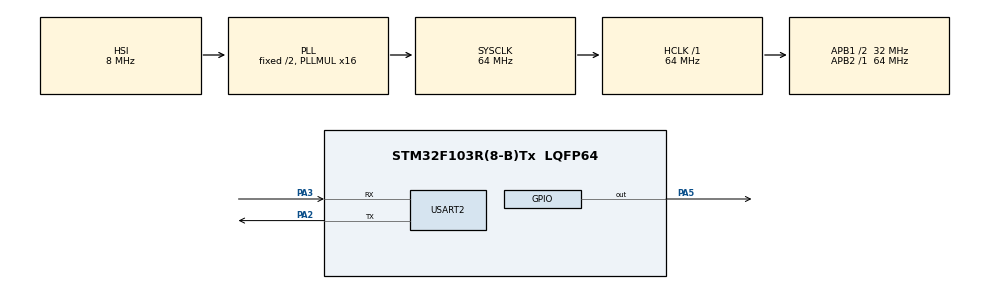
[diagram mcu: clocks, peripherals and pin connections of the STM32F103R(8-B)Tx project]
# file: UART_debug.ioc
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Mcu.Family=STM32F1
RCC.APB1CLKDivider=RCC_HCLK_DIV2
RCC.SYSCLKSource=RCC_SYSCLKSOURCE_PLLCLK
ProjectManager.StackSize=0x400
PA13.Signal=SYS_JTMS-SWDIO
PA3.Mode=Asynchronous
ProjectManager.TargetToolchain=STM32CubeIDE
RCC.HCLKFreq_Value=64000000
RCC.APB2TimFreq_Value=64000000
RCC.USBFreq_Value=64000000
RCC.AHBFreq_Value=64000000
PA5.Signal=GPIO_Output
board=custom
RCC.PLLMUL=RCC_PLL_MUL16
RCC.APB2Freq_Value=64000000
PA14.Mode=Serial_Wire
PA13.Mode=Serial_Wire
Mcu.Name=STM32F103R(8-B)Tx
PA2.Signal=USART2_TX
RCC.SYSCLKFreq_VALUE=64000000
Mcu.Package=LQFP64
USART2.VirtualMode=VM_ASYNC
PA14.Signal=SYS_JTCK-SWCLK
ProjectManager.HeapSize=0x200
NVIC.PriorityGroup=NVIC_PRIORITYGROUP_4
RCC.APB1TimFreq_Value=64000000
PA2.Mode=Asynchronous
RCC.APB1Freq_Value=32000000
PA3.Signal=USART2_RX

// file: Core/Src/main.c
/* USER CODE BEGIN Header */
/**
  ******************************************************************************
  * @file           : main.c
  * @brief          : Main program body
  ******************************************************************************
  * @attention
  *
  * <h2><center>&copy; Copyright (c) 2021 STMicroelectronics.
  * All rights reserved.</center></h2>
  *
  * This software component is licensed by ST under Ultimate Liberty license
  * SLA0044, the "License"; You may not use this file except in compliance with
  * the License. You may obtain a copy of the License at:
  *                             www.st.com/SLA0044
  *
  ******************************************************************************
  */
/* USER CODE END Header */
#include "main.h"

UART_HandleTypeDef huart2;

void SystemClock_Config(void);
static void MX_GPIO_Init(void);
static void MX_USART2_UART_Init(void);
/* USER CODE BEGIN PFP */
// uint8_t CDC_Transmit_FS(uint8_t* Buf, uint16_t Len);
/* USER CODE END PFP */

int main(void)
{

  /* MCU Configuration--------------------------------------------------------*/

  /* Reset of all peripherals, Initializes the Flash interface and the Systick. */
  HAL_Init();

  /* Configure the system clock */
  SystemClock_Config();

  /* Initialize all configured peripherals */
  MX_GPIO_Init();
  MX_USART2_UART_Init();
  /* USER CODE BEGIN 2 */
  uint8_t data[256];
  HAL_StatusTypeDef s;
  uint8_t *string;
  /* USER CODE END 2 */

  /* Infinite loop */
  /* USER CODE BEGIN WHILE */
  while (1)
  {
	string = "Timeout /r/n";
	s = HAL_UART_Receive(&huart2, data, 1, 3000);
	if(s == HAL_TIMEOUT){
		HAL_UART_Transmit(&huart2, string, 15, 10);
	}else if(s == HAL_OK){
		HAL_UART_Transmit(&huart2, data, 1, 10);
	}
    /* USER CODE END WHILE */

  }
}

void SystemClock_Config(void)
{
  RCC_OscInitTypeDef RCC_OscInitStruct = {0};
  RCC_ClkInitTypeDef RCC_ClkInitStruct = {0};

  /** Initializes the RCC Oscillators according to the specified parameters
  * in the RCC_OscInitTypeDef structure.
  */
  RCC_OscInitStruct.OscillatorType = RCC_OSCILLATORTYPE_HSI;
  RCC_OscInitStruct.HSIState = RCC_HSI_ON;
  RCC_OscInitStruct.HSICalibrationValue = RCC_HSICALIBRATION_DEFAULT;
  RCC_OscInitStruct.PLL.PLLState = RCC_PLL_ON;
  RCC_OscInitStruct.PLL.PLLSource = RCC_PLLSOURCE_HSI_DIV2;
  RCC_OscInitStruct.PLL.PLLMUL = RCC_PLL_MUL16;
  if (HAL_RCC_OscConfig(&RCC_OscInitStruct) != HAL_OK)
  {
    Error_Handler();
  }
  /** Initializes the CPU, AHB and APB buses clocks
  */
  RCC_ClkInitStruct.ClockType = RCC_CLOCKTYPE_HCLK|RCC_CLOCKTYPE_SYSCLK
                              |RCC_CLOCKTYPE_PCLK1|RCC_CLOCKTYPE_PCLK2;
  RCC_ClkInitStruct.SYSCLKSource = RCC_SYSCLKSOURCE_PLLCLK;
  RCC_ClkInitStruct.AHBCLKDivider = RCC_SYSCLK_DIV1;
  RCC_ClkInitStruct.APB1CLKDivider = RCC_HCLK_DIV2;
  RCC_ClkInitStruct.APB2CLKDivider = RCC_HCLK_DIV1;

  if (HAL_RCC_ClockConfig(&RCC_ClkInitStruct, FLASH_LATENCY_2) != HAL_OK)
  {
    Error_Handler();
  }
}

static void MX_USART2_UART_Init(void)
{

  huart2.Instance = USART2;
  huart2.Init.BaudRate = 115200;
  huart2.Init.WordLength = UART_WORDLENGTH_8B;
  huart2.Init.StopBits = UART_STOPBITS_1;
  huart2.Init.Parity = UART_PARITY_NONE;
  huart2.Init.Mode = UART_MODE_TX_RX;
  huart2.Init.HwFlowCtl = UART_HWCONTROL_NONE;
  huart2.Init.OverSampling = UART_OVERSAMPLING_16;
  if (HAL_UART_Init(&huart2) != HAL_OK)
  {
    Error_Handler();
  }

}

static void MX_GPIO_Init(void)
{
  GPIO_InitTypeDef GPIO_InitStruct = {0};

  /* GPIO Ports Clock Enable */
  __HAL_RCC_GPIOA_CLK_ENABLE();

  /*Configure GPIO pin Output Level */
  HAL_GPIO_WritePin(GPIOA, GPIO_PIN_5, GPIO_PIN_RESET);

  /*Configure GPIO pin : PA5 */
  GPIO_InitStruct.Pin = GPIO_PIN_5;
  GPIO_InitStruct.Mode = GPIO_MODE_OUTPUT_PP;
  GPIO_InitStruct.Pull = GPIO_NOPULL;
  GPIO_InitStruct.Speed = GPIO_SPEED_FREQ_LOW;
  HAL_GPIO_Init(GPIOA, &GPIO_InitStruct);

}

void Error_Handler(void)
{
  __disable_irq();
  while (1)
  {
  }
}

/************************ (C) COPYRIGHT STMicroelectronics *****END OF FILE****/
